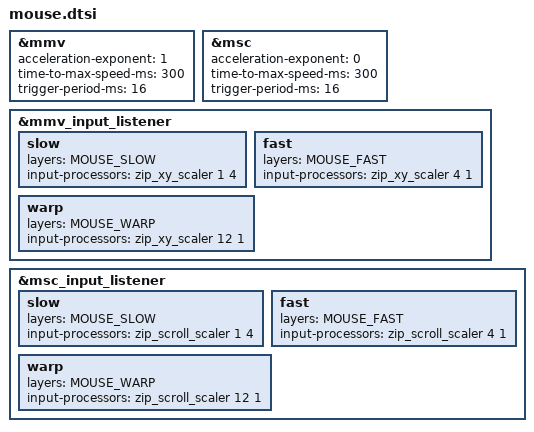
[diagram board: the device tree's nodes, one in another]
#define ZMK_POINTING_DEFAULT_MOVE_VAL 600  // 600
#define ZMK_POINTING_DEFAULT_SCRL_VAL 10   // 10

#include <dt-bindings/zmk/pointing.h>
#include <input/processors.dtsi>

&mmv {
    acceleration-exponent = <1>;      // 1
    time-to-max-speed-ms = <300>;     // 300
    trigger-period-ms = <16>;
};

&msc {
    acceleration-exponent = <0>;      // 0
    time-to-max-speed-ms = <300>;      // 300
    trigger-period-ms = <16>;
};

&mmv_input_listener {
    slow {
        layers = <MOUSE_SLOW>;
        input-processors = <&zip_xy_scaler 1 4>;
    };
};

&mmv_input_listener {
    fast {
        layers = <MOUSE_FAST>;
        input-processors = <&zip_xy_scaler 4 1>;
    };
};

&mmv_input_listener {
    warp {
        layers = <MOUSE_WARP>;
        input-processors = <&zip_xy_scaler 12 1>;
    };
};

&msc_input_listener {
    slow {
        layers = <MOUSE_SLOW>;
        input-processors = <&zip_scroll_scaler 1 4>;
    };
};

&msc_input_listener {
    fast {
        layers = <MOUSE_FAST>;
        input-processors = <&zip_scroll_scaler 4 1>;
    };
};

&msc_input_listener {
    warp {
        layers = <MOUSE_WARP>;
        input-processors = <&zip_scroll_scaler 12 1>;
    };
};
